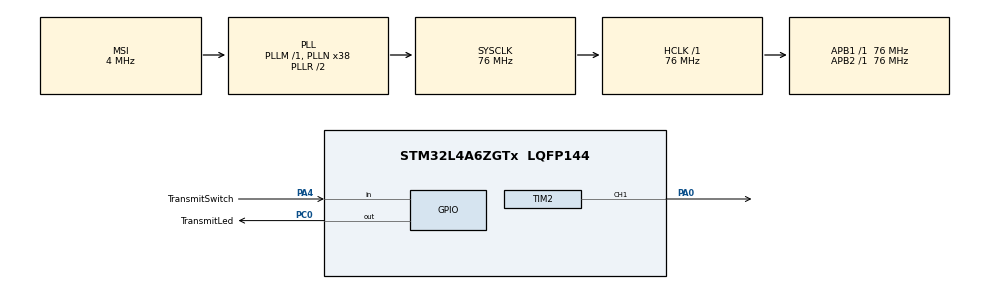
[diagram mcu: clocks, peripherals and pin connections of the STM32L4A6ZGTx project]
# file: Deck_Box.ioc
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Mcu.Family=STM32L4
Mcu.Name=STM32L4A6ZGTx
Mcu.Package=LQFP144
NVIC.PriorityGroup=NVIC_PRIORITYGROUP_4
PA0.Signal=S_TIM2_CH1
PA4.GPIO_Label=TransmitSwitch
PA4.Signal=GPIO_Input
PC0.GPIO_Label=TransmitLed
PC0.Signal=GPIO_Output
PH0-OSC_IN\ (PH0).Mode=HSE-External-Oscillator
PH0-OSC_IN\ (PH0).Signal=RCC_OSC_IN
PH1-OSC_OUT\ (PH1).Mode=HSE-External-Oscillator
PH1-OSC_OUT\ (PH1).Signal=RCC_OSC_OUT
ProjectManager.HeapSize=0x200
ProjectManager.StackSize=0x400
ProjectManager.TargetToolchain=STM32CubeIDE
RCC.ADCFreq_Value=16000000
RCC.AHBFreq_Value=76000000
RCC.APB1Freq_Value=76000000
RCC.APB1TimFreq_Value=76000000
RCC.APB2Freq_Value=76000000
RCC.APB2TimFreq_Value=76000000
RCC.CortexFreq_Value=76000000
RCC.HCLKFreq_Value=76000000
RCC.HSE_VALUE=8000000
RCC.HSI48_VALUE=48000000
RCC.HSI_VALUE=16000000
RCC.LSE_VALUE=32768
RCC.MSI_VALUE=4000000
RCC.PLLN=38
RCC.SYSCLKFreq_VALUE=76000000
RCC.SYSCLKSource=RCC_SYSCLKSOURCE_PLLCLK
RCC.USBFreq_Value=16000000
RCC.VCOOutputFreq_Value=152000000
SH.S_TIM2_CH1.0=TIM2_CH1,PWM Generation1 CH1
TIM2.AutoReloadPreload=TIM_AUTORELOAD_PRELOAD_ENABLE
TIM2.Channel-PWM\ Generation1\ CH1=TIM_CHANNEL_1
TIM2.Period=400
TIM2.Pulse-PWM\ Generation1\ CH1=200
VP_TIM2_VS_ClockSourceINT.Mode=Internal
VP_TIM4_VS_ClockSourceINT.Mode=Internal
board=custom

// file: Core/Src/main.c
/* USER CODE BEGIN Header */
/**
  ******************************************************************************
  * @file           : main.c
  * @brief          : Main program body
  ******************************************************************************
  * @attention
  *
  * Copyright (c) 2022 STMicroelectronics.
  * All rights reserved.
  *
  * This software is licensed under terms that can be found in the LICENSE file
  * in the root directory of this software component.
  * If no LICENSE file comes with this software, it is provided AS-IS.
  *
  ******************************************************************************
  */
/* USER CODE END Header */
#include "main.h"

TIM_HandleTypeDef htim2;
TIM_HandleTypeDef htim4;

void SystemClock_Config(void);
static void MX_GPIO_Init(void);
static void MX_TIM2_Init(void);
static void MX_TIM4_Init(void);
/* USER CODE BEGIN PFP */
volatile static uint32_t gu32_ticks = 0;
/* USER CODE END PFP */

/* USER CODE BEGIN 0 */

/*
 	 This delay function is not used at the moment
*/

void delay_ms(uint16_t au16_ms)
{
    while(au16_ms > 0)
    {
    	htim4.Instance->CNT = 0;
    	au16_ms--;
    	while (htim4.Instance->CNT < 1000);
    }
}

/*
	TIM 2 square wave function
  	output at PA0 GPIO
*/

void square_wave(int duty_cycle, int freq)
{
	// setting frequency
	int freq_arr = 76000000/(freq*1000);
	TIM2->ARR = freq_arr;

	//setting Duty Cycle
	TIM2->CCR1 = duty_cycle * freq_arr / 100;

}

int main(void)
{

  /* Reset of all peripherals, Initializes the Flash interface and the Systick. */
  HAL_Init();

  /* Configure the system clock */
  SystemClock_Config();

  /* Initialize all configured peripherals */
  MX_GPIO_Init();
  MX_TIM2_Init();
  MX_TIM4_Init();

  // Starts PWM Signal Generation
  HAL_TIM_PWM_Start(&htim2, TIM_CHANNEL_1); //190,
  //HAL_TIM_PWM_Start(&htim1, TIM_CHANNEL_1);

  uint16_t f1 = 411 * 5; // 411
  uint16_t f2 = 380 * 5; // 380

  while (1)
  {
	  /* Signal out at pin PA0
	   * transmit switch read PA3
	   * Transmit LED out PC0 xx
	   */

	  //square_wave( 50, 50); //duty cycle, freq

	  // if transmit switch is turned on
	  if(HAL_GPIO_ReadPin(TransmitSwitch_GPIO_Port,TransmitSwitch_Pin)==1){

		  //int frq1 = 190; //in kHz
		  int ARR1 = f1;//411;//422;//400;//76000000/(frq1*1000); for freq 190k
		  //int frq2 = 210; //in Khz
		  int ARR2 = f2;//380;//362; //76000000/(frq2*1000); for freq 210k

		  /* CRRx = Duty Cycle * ARRx /100
		   * 200 = 50 * 400 / 100
		   * 181 = 50 * 362 / 100
		   * */

		  TIM2->CCR1 = 205;//200;
		  TIM2->ARR = ARR1; //freq1
		  HAL_Delay(1000);

		  TIM2->CCR1 = 190;//181;
		  TIM2->ARR = ARR2; //setting freq2
		  HAL_Delay(1000);

	  }
	  else{
		  TIM2->CCR1 = 0;
	  }

  }
}

void SystemClock_Config(void)
{
  RCC_OscInitTypeDef RCC_OscInitStruct = {0};
  RCC_ClkInitTypeDef RCC_ClkInitStruct = {0};

  /** Configure the main internal regulator output voltage
  */
  if (HAL_PWREx_ControlVoltageScaling(PWR_REGULATOR_VOLTAGE_SCALE1) != HAL_OK)
  {
    Error_Handler();
  }

  /** Initializes the RCC Oscillators according to the specified parameters
  * in the RCC_OscInitTypeDef structure.
  */
  RCC_OscInitStruct.OscillatorType = RCC_OSCILLATORTYPE_MSI;
  RCC_OscInitStruct.MSIState = RCC_MSI_ON;
  RCC_OscInitStruct.MSICalibrationValue = 0;
  RCC_OscInitStruct.MSIClockRange = RCC_MSIRANGE_6;
  RCC_OscInitStruct.PLL.PLLState = RCC_PLL_ON;
  RCC_OscInitStruct.PLL.PLLSource = RCC_PLLSOURCE_MSI;
  RCC_OscInitStruct.PLL.PLLM = 1;
  RCC_OscInitStruct.PLL.PLLN = 38;
  RCC_OscInitStruct.PLL.PLLP = RCC_PLLP_DIV2;
  RCC_OscInitStruct.PLL.PLLQ = RCC_PLLQ_DIV2;
  RCC_OscInitStruct.PLL.PLLR = RCC_PLLR_DIV2;
  if (HAL_RCC_OscConfig(&RCC_OscInitStruct) != HAL_OK)
  {
    Error_Handler();
  }

  /** Initializes the CPU, AHB and APB buses clocks
  */
  RCC_ClkInitStruct.ClockType = RCC_CLOCKTYPE_HCLK|RCC_CLOCKTYPE_SYSCLK
                              |RCC_CLOCKTYPE_PCLK1|RCC_CLOCKTYPE_PCLK2;
  RCC_ClkInitStruct.SYSCLKSource = RCC_SYSCLKSOURCE_PLLCLK;
  RCC_ClkInitStruct.AHBCLKDivider = RCC_SYSCLK_DIV1;
  RCC_ClkInitStruct.APB1CLKDivider = RCC_HCLK_DIV1;
  RCC_ClkInitStruct.APB2CLKDivider = RCC_HCLK_DIV1;

  if (HAL_RCC_ClockConfig(&RCC_ClkInitStruct, FLASH_LATENCY_4) != HAL_OK)
  {
    Error_Handler();
  }
}

static void MX_TIM2_Init(void)
{

  TIM_ClockConfigTypeDef sClockSourceConfig = {0};
  TIM_MasterConfigTypeDef sMasterConfig = {0};
  TIM_OC_InitTypeDef sConfigOC = {0};

  htim2.Instance = TIM2;
  htim2.Init.Prescaler = 0;
  htim2.Init.CounterMode = TIM_COUNTERMODE_UP;
  htim2.Init.Period = 400;
  htim2.Init.ClockDivision = TIM_CLOCKDIVISION_DIV1;
  htim2.Init.AutoReloadPreload = TIM_AUTORELOAD_PRELOAD_ENABLE;
  if (HAL_TIM_Base_Init(&htim2) != HAL_OK)
  {
    Error_Handler();
  }
  sClockSourceConfig.ClockSource = TIM_CLOCKSOURCE_INTERNAL;
  if (HAL_TIM_ConfigClockSource(&htim2, &sClockSourceConfig) != HAL_OK)
  {
    Error_Handler();
  }
  if (HAL_TIM_PWM_Init(&htim2) != HAL_OK)
  {
    Error_Handler();
  }
  sMasterConfig.MasterOutputTrigger = TIM_TRGO_RESET;
  sMasterConfig.MasterSlaveMode = TIM_MASTERSLAVEMODE_DISABLE;
  if (HAL_TIMEx_MasterConfigSynchronization(&htim2, &sMasterConfig) != HAL_OK)
  {
    Error_Handler();
  }
  sConfigOC.OCMode = TIM_OCMODE_PWM1;
  sConfigOC.Pulse = 200;
  sConfigOC.OCPolarity = TIM_OCPOLARITY_HIGH;
  sConfigOC.OCFastMode = TIM_OCFAST_DISABLE;
  if (HAL_TIM_PWM_ConfigChannel(&htim2, &sConfigOC, TIM_CHANNEL_1) != HAL_OK)
  {
    Error_Handler();
  }
  HAL_TIM_MspPostInit(&htim2);

}

static void MX_TIM4_Init(void)
{

  /* USER CODE BEGIN TIM4_Init 0 */
	gu32_ticks = (HAL_RCC_GetHCLKFreq() / 1000000);
  /* USER CODE END TIM4_Init 0 */

  TIM_ClockConfigTypeDef sClockSourceConfig = {0};
  TIM_MasterConfigTypeDef sMasterConfig = {0};

  htim4.Instance = TIM4;
  htim4.Init.Prescaler = 0;
  htim4.Init.CounterMode = TIM_COUNTERMODE_UP;
  htim4.Init.Period = 65535;
  htim4.Init.ClockDivision = TIM_CLOCKDIVISION_DIV1;
  htim4.Init.AutoReloadPreload = TIM_AUTORELOAD_PRELOAD_DISABLE;
  if (HAL_TIM_Base_Init(&htim4) != HAL_OK)
  {
    Error_Handler();
  }
  sClockSourceConfig.ClockSource = TIM_CLOCKSOURCE_INTERNAL;
  if (HAL_TIM_ConfigClockSource(&htim4, &sClockSourceConfig) != HAL_OK)
  {
    Error_Handler();
  }
  sMasterConfig.MasterOutputTrigger = TIM_TRGO_RESET;
  sMasterConfig.MasterSlaveMode = TIM_MASTERSLAVEMODE_DISABLE;
  if (HAL_TIMEx_MasterConfigSynchronization(&htim4, &sMasterConfig) != HAL_OK)
  {
    Error_Handler();
  }
  /* USER CODE BEGIN TIM4_Init 2 */
  HAL_TIM_Base_Start(&htim4);
  /* USER CODE END TIM4_Init 2 */

}

static void MX_GPIO_Init(void)
{
  GPIO_InitTypeDef GPIO_InitStruct = {0};

  /* GPIO Ports Clock Enable */
  __HAL_RCC_GPIOH_CLK_ENABLE();
  __HAL_RCC_GPIOC_CLK_ENABLE();
  __HAL_RCC_GPIOA_CLK_ENABLE();

  /*Configure GPIO pin Output Level */
  HAL_GPIO_WritePin(TransmitLed_GPIO_Port, TransmitLed_Pin, GPIO_PIN_RESET);

  /*Configure GPIO pin : TransmitLed_Pin */
  GPIO_InitStruct.Pin = TransmitLed_Pin;
  GPIO_InitStruct.Mode = GPIO_MODE_OUTPUT_PP;
  GPIO_InitStruct.Pull = GPIO_NOPULL;
  GPIO_InitStruct.Speed = GPIO_SPEED_FREQ_LOW;
  HAL_GPIO_Init(TransmitLed_GPIO_Port, &GPIO_InitStruct);

  /*Configure GPIO pin : TransmitSwitch_Pin */
  GPIO_InitStruct.Pin = TransmitSwitch_Pin;
  GPIO_InitStruct.Mode = GPIO_MODE_INPUT;
  GPIO_InitStruct.Pull = GPIO_NOPULL;
  HAL_GPIO_Init(TransmitSwitch_GPIO_Port, &GPIO_InitStruct);

}

void Error_Handler(void)
{
  __disable_irq();
  while (1)
  {
  }
}
